# LPC11Uxx register map
File version: 7
CPU: CM0 r0p0, little endian, no MPU, no FPU, 0x2 interrupt priority bits, 0x0 interrupts
Registers are 32-bit, read-write, reset 0x0 unless marked. A register's access mark holds for its fields unless they carry their own. Offsets are from the block's base; [hi:lo] are bit positions; {n}, {i} and the like mark numbered series; 'fields as' and 'values as' point back to an identical list.

## GPIO_PORT
Base 0x50000000
{0x0+i} B{i:02} 8-bit (i=0..9) — Byte pin registers port 0; pins PIO0_0 to PIO0_31
  [0] PBYTE — Read: state of the pin P0_n, regardless of direction, masking, or alternate function, except that pins configured as analog I/O always read as 0. Write: loads the pin's output bit.
{0x0+i} B{i:03} 8-bit (i=10..31) — Byte pin registers port 0; pins PIO0_0 to PIO0_31
  fields as B00
0x20 B132 8-bit — Byte pin registers port 1
  [0] PBYTE — Read: state of the pin P1_n, regardless of direction, masking, or alternate function, except that pins configured as analog I/O always read as 0. Write: loads the pin's output bit.
0x21 B133 8-bit — Byte pin registers port 1
  fields as B132
0x22 B134 8-bit — Byte pin registers port 1
  fields as B132
0x23 B135 8-bit — Byte pin registers port 1
  fields as B132
0x24 B136 8-bit — Byte pin registers port 1
  fields as B132
0x25 B137 8-bit — Byte pin registers port 1
  fields as B132
0x26 B138 8-bit — Byte pin registers port 1
  fields as B132
0x27 B139 8-bit — Byte pin registers port 1
  fields as B132
0x28 B140 8-bit — Byte pin registers port 1
  fields as B132
0x29 B141 8-bit — Byte pin registers port 1
  fields as B132
0x2A B142 8-bit — Byte pin registers port 1
  fields as B132
0x2B B143 8-bit — Byte pin registers port 1
  fields as B132
0x2C B144 8-bit — Byte pin registers port 1
  fields as B132
0x2D B145 8-bit — Byte pin registers port 1
  fields as B132
0x2E B146 8-bit — Byte pin registers port 1
  fields as B132
0x2F B147 8-bit — Byte pin registers port 1
  fields as B132
0x30 B148 8-bit — Byte pin registers port 1
  fields as B132
0x31 B149 8-bit — Byte pin registers port 1
  fields as B132
0x32 B150 8-bit — Byte pin registers port 1
  fields as B132
0x33 B151 8-bit — Byte pin registers port 1
  fields as B132
0x34 B152 8-bit — Byte pin registers port 1
  fields as B132
0x35 B153 8-bit — Byte pin registers port 1
  fields as B132
0x36 B154 8-bit — Byte pin registers port 1
  fields as B132
0x37 B155 8-bit — Byte pin registers port 1
  fields as B132
0x38 B156 8-bit — Byte pin registers port 1
  fields as B132
0x39 B157 8-bit — Byte pin registers port 1
  fields as B132
0x3A B158 8-bit — Byte pin registers port 1
  fields as B132
0x3B B159 8-bit — Byte pin registers port 1
  fields as B132
0x3C B160 8-bit — Byte pin registers port 1
  fields as B132
0x3D B161 8-bit — Byte pin registers port 1
  fields as B132
0x3E B162 8-bit — Byte pin registers port 1
  fields as B132
0x3F B163 8-bit — Byte pin registers port 1
  fields as B132
{0x1000+4i} W{i} (i=0..31) — Word pin registers port 0
  [31:0] PWORD — Read 0: pin is LOW. Write 0: clear output bit. Read 0xFFFF FFFF: pin is HIGH. Write any value 0x0000 0001 to 0xFFFF FFFF: set output bit. Only 0 or 0xFFFF FFFF can be read. Writing any value other than 0 will set the output bit.
{0x1000+4i} W{i} (i=32..63) — Word pin registers port 1
  fields as W0
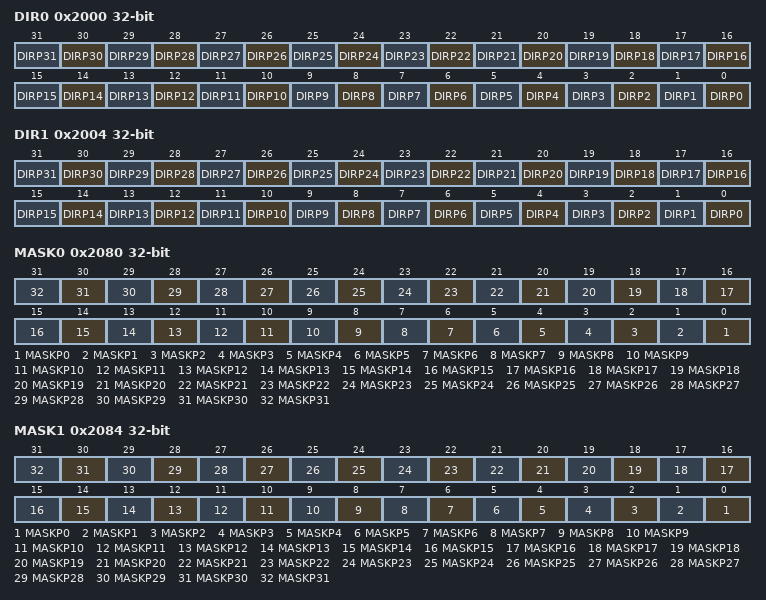
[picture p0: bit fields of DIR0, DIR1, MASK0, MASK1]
0x2000 DIR0 — Direction registers port 0/1
  [n] DIRP{n} (n=0..31) — Selects pin direction for pin P0/1_n (bit 0 = P0/1_0, bit 1 = P0_1, ..., bit 31 = P0/1_31). 0 = input. 1 = output.
0x2004 DIR1 — Direction registers port 0/1
  fields as DIR0
0x2080 MASK0 — Mask register port 0/1
  [n] MASKP{n} (n=0..31) — Controls which bits corresponding to P0/1_n are active in the P0/1 PIN register (bit 0 = P0/1_0, bit 1 = P0/1_1, ..., bit 31 = P0/1_31). 0 = Read MPORT: pin state; write MPORT: load output bit. 1 = Read MPORT: 0; write MPORT: output bit not affected.
0x2084 MASK1 — Mask register port 0/1
  fields as MASK0
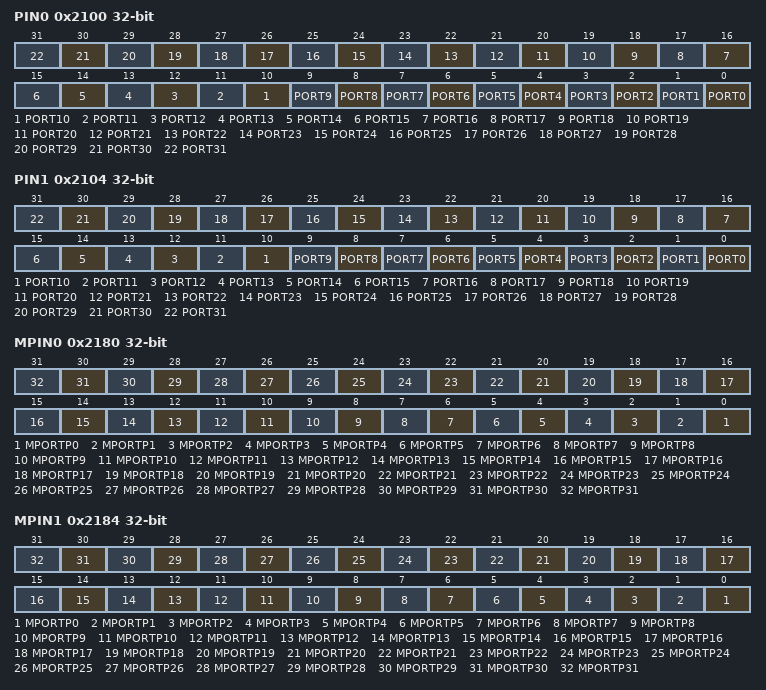
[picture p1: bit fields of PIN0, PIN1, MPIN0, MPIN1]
0x2100 PIN0 — Portpin register port 0
  [n] PORT{n} (n=0..31) — Reads pin states or loads output bits (bit 0 = P0/1_0, bit 1 = P0/1_1, ..., bit 31 = P0/1_31). 0 = Read: pin is low; write: clear output bit. 1 = Read: pin is high; write: set output bit.
0x2104 PIN1 — Portpin register port 0
  fields as PIN0
0x2180 MPIN0 — Masked port register port 0/1
  [n] MPORTP{n} (n=0..31) — Masked port register (bit 0 = P0/1_0, bit 1 = P0/1_1, ..., bit 31 = P0/1_31). 0 = Read: pin is LOW and/or the corresponding bit in the MASK register is 1; write: clear output bit if the corresponding bit in the MASK register is 0. 1 = Read: pin is HIGH and the corresponding bit in the MASK register is 0; write: set output bit if the corresponding bit in the MASK register is 0.
0x2184 MPIN1 — Masked port register port 0/1
  fields as MPIN0
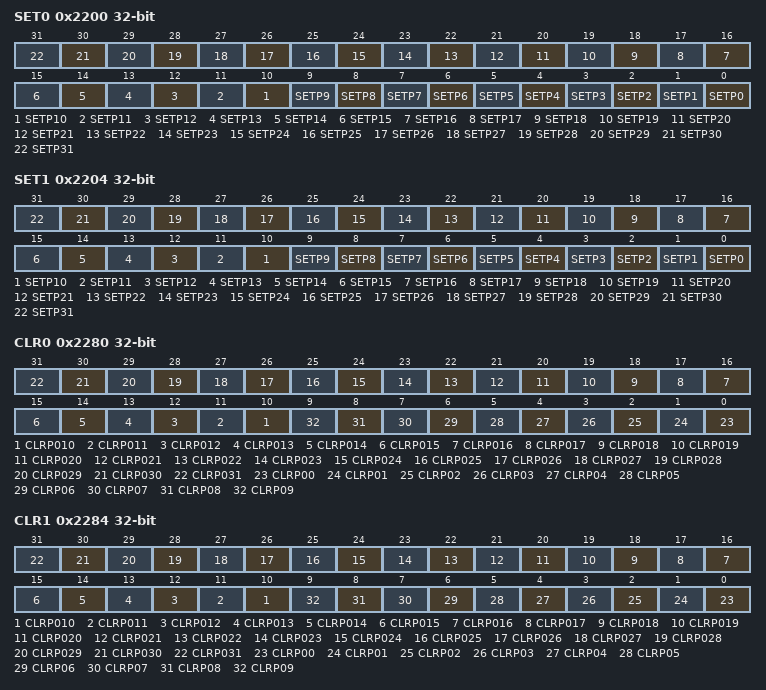
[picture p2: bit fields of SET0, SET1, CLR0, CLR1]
0x2200 SET0 — Write: Set register for port 0/1 Read: output bits for port 0/1
  [n] SETP{n} (n=0..31) — Read or set output bits. 0 = Read: output bit: write: no operation. 1 = Read: output bit; write: set output bit.
0x2204 SET1 — Write: Set register for port 0/1 Read: output bits for port 0/1
  fields as SET0
0x2280 CLR0 wo reset not defined — Clear port 0/1
  [n] CLRP{n:03} (n=10..31) — Clear output bits: 0 = No operation. 1 = Clear output bit.
  [n] CLRP{n:02} (n=0..9) — Clear output bits: 0 = No operation. 1 = Clear output bit.
0x2284 CLR1 wo reset not defined — Clear port 0/1
  fields as CLR0
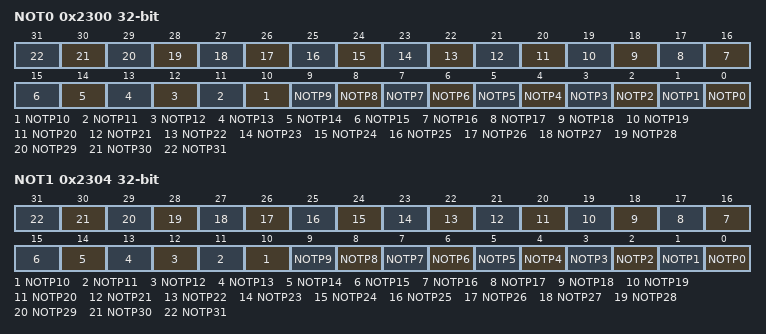
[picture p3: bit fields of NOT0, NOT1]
0x2300 NOT0 wo reset not defined — Toggle port 0/1
  [n] NOTP{n} (n=0..31) — Toggle output bits: 0 = no operation. 1 = Toggle output bit.
0x2304 NOT1 wo reset not defined — Toggle port 0/1
  fields as NOT0
